AUTOSAR XML (schema 314)
package /ComponentType
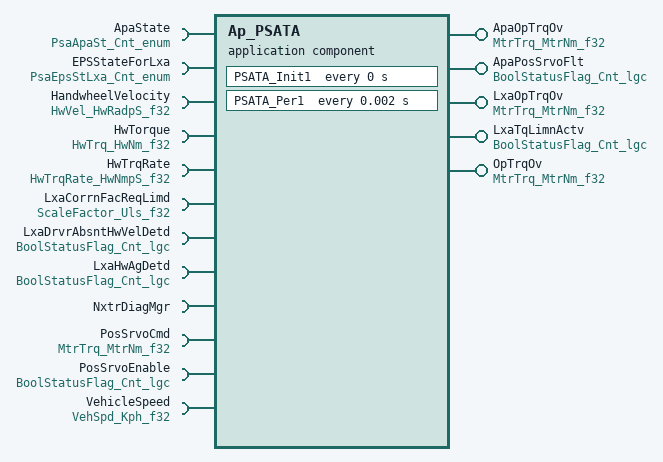
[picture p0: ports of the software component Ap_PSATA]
  application software component type Ap_PSATA
    5 x provide port:
      ApaOpTrqOv: unqueued-sender-com-spec{data-element=MtrNm_f32, can-invalidate=false, init-value=D_ZERO_ULS_F32}, provided-interface=MtrTrq_MtrNm_f32
      ApaPosSrvoFlt: unqueued-sender-com-spec{data-element=Cnt_lgc, can-invalidate=false, init-value=D_FALSE_CNT_LGC}, provided-interface=BoolStatusFlag_Cnt_lgc
      LxaOpTrqOv: unqueued-sender-com-spec{data-element=MtrNm_f32, can-invalidate=false, init-value=D_ZERO_ULS_F32}, provided-interface=MtrTrq_MtrNm_f32
      LxaTqLimnActv: unqueued-sender-com-spec{data-element=Cnt_lgc, can-invalidate=false, init-value=D_FALSE_CNT_LGC}, provided-interface=BoolStatusFlag_Cnt_lgc
      OpTrqOv: unqueued-sender-com-spec{data-element=MtrNm_f32, can-invalidate=false, init-value=D_ZERO_ULS_F32}, provided-interface=MtrTrq_MtrNm_f32
    12 x require port:
      ApaState: unqueued-receiver-com-spec{data-element=Cnt_enum, init-value=D_PSAAPASTINIT_CNT_ENUM}, required-interface=PsaApaSt_Cnt_enum
      EPSStateForLxa: unqueued-receiver-com-spec{data-element=Cnt_enum, init-value=D_PSAEPSSTLXAINIT_CNT_ENUM}, required-interface=PsaEpsStLxa_Cnt_enum
      HandwheelVelocity: unqueued-receiver-com-spec{data-element=HwRadpS_f32, init-value=D_ZERO_ULS_F32}, required-interface=HwVel_HwRadpS_f32
      HwTorque: unqueued-receiver-com-spec{data-element=HwNm_f32, init-value=D_ZERO_ULS_F32}, required-interface=HwTrq_HwNm_f32
      HwTrqRate: unqueued-receiver-com-spec{data-element=HwNmpS_f32, init-value=D_ZERO_ULS_F32}, required-interface=HwTrqRate_HwNmpS_f32
      LxaCorrnFacReqLimd: unqueued-receiver-com-spec{data-element=Uls_f32, init-value=D_ZERO_ULS_F32}, required-interface=ScaleFactor_Uls_f32
      LxaDrvrAbsntHwVelDetd: unqueued-receiver-com-spec{data-element=Cnt_lgc, init-value=D_FALSE_CNT_LGC}, required-interface=BoolStatusFlag_Cnt_lgc
      LxaHwAgDetd: unqueued-receiver-com-spec{data-element=Cnt_lgc, init-value=D_FALSE_CNT_LGC}, required-interface=BoolStatusFlag_Cnt_lgc
      NxtrDiagMgr: required-com-specs=[GetNTCActive, GetNTCFailed, GetNTCStatus, SetNTCStatus], required-interface=NxtrDiagMgr
      PosSrvoCmd: unqueued-receiver-com-spec{data-element=MtrNm_f32, init-value=D_ZERO_ULS_F32}, required-interface=MtrTrq_MtrNm_f32
      PosSrvoEnable: unqueued-receiver-com-spec{data-element=Cnt_lgc, init-value=D_FALSE_CNT_LGC}, required-interface=BoolStatusFlag_Cnt_lgc
      VehicleSpeed: unqueued-receiver-com-spec{data-element=Kph_f32, init-value=D_ZERO_ULS_F32}, required-interface=VehSpd_Kph_f32
  internal behavior Ap_PSATA_InternalBehavior: component=Ap_PSATA
    timing event PSATA_Init1_InitEvent: start-on-event=PSATA_Init1, period=0
    timing event TMT_PSATA_Per1: start-on-event=PSATA_Per1, period=0.002
    port-api-options:
      enable-take-address=false, indirect-api=false, port=ApaOpTrqOv
      enable-take-address=false, indirect-api=false, port=ApaPosSrvoFlt
      enable-take-address=false, indirect-api=false, port=ApaState
      enable-take-address=false, indirect-api=false, port=EPSStateForLxa
      enable-take-address=false, indirect-api=false, port=HandwheelVelocity
      enable-take-address=false, indirect-api=false, port=HwTorque
      enable-take-address=false, indirect-api=false, port=HwTrqRate
      enable-take-address=false, indirect-api=false, port=LxaCorrnFacReqLimd
      enable-take-address=false, indirect-api=false, port=LxaDrvrAbsntHwVelDetd
      enable-take-address=false, indirect-api=false, port=LxaHwAgDetd
      enable-take-address=false, indirect-api=false, port=LxaOpTrqOv
      enable-take-address=false, indirect-api=false, port=LxaTqLimnActv
      enable-take-address=false, indirect-api=false, port=NxtrDiagMgr
      enable-take-address=false, indirect-api=false, port=OpTrqOv
      enable-take-address=false, indirect-api=false, port=PosSrvoCmd
      enable-take-address=false, indirect-api=false, port=PosSrvoEnable
      enable-take-address=false, indirect-api=false, port=VehicleSpeed
    runnable PSATA_Init1  # Function initialization
      sync call SC_NxtrDiagMgr_SetNTCStatus: operation=NxtrDiagMgr.SetNTCStatus, timeout=0
    runnable PSATA_Per1  # Periodic Runnable execute at every 0.002 sec. Shouble be executed after SF020A PosnTrakgServo and before SF004B Assist Summation and Limiting
      11 x data read access:
        READ_ApaState_Cnt_enum: data-element=ApaState.Cnt_enum
        READ_EPSStateForLxa_Cnt_enum: data-element=EPSStateForLxa.Cnt_enum
        READ_HandwheelVelocity_HwRadpS_f32: data-element=HandwheelVelocity.HwRadpS_f32
        READ_HwTorque_HwNm_f32: data-element=HwTorque.HwNm_f32
        READ_HwTrqRate_HwNmpS_f32: data-element=HwTrqRate.HwNmpS_f32
        READ_LxaCorrnFacReqLimd_Uls_f32: data-element=LxaCorrnFacReqLimd.Uls_f32
        READ_LxaDrvrAbsntHwVelDetd_Cnt_lgc: data-element=LxaDrvrAbsntHwVelDetd.Cnt_lgc
        READ_LxaHwAgDetd_Cnt_lgc: data-element=LxaHwAgDetd.Cnt_lgc
        READ_PosSrvoCmd_MtrNm_f32: data-element=PosSrvoCmd.MtrNm_f32
        READ_PosSrvoEnable_Cnt_lgc: data-element=PosSrvoEnable.Cnt_lgc
        READ_VehicleSpeed_Kph_f32: data-element=VehicleSpeed.Kph_f32
      5 x data write access:
        WRITE_ApaOpTrqOv_MtrNm_f32: data-element=ApaOpTrqOv.MtrNm_f32
        WRITE_ApaPosSrvoFlt_Cnt_lgc: data-element=ApaPosSrvoFlt.Cnt_lgc
        WRITE_LxaOpTrqOv_MtrNm_f32: data-element=LxaOpTrqOv.MtrNm_f32
        WRITE_LxaTqLimnActv_Cnt_lgc: data-element=LxaTqLimnActv.Cnt_lgc
        WRITE_OpTrqOv_MtrNm_f32: data-element=OpTrqOv.MtrNm_f32
      sync call SC_NxtrDiagMgr_SetNTCStatus: operation=NxtrDiagMgr.SetNTCStatus, timeout=0
  swc implementation Ap_PSATA_Implementation: behavior=Ap_PSATA_InternalBehavior
    code-descriptors:
      code Code: type=SRC
